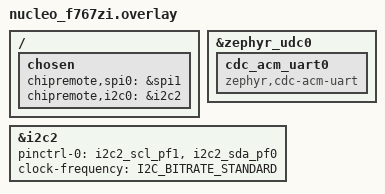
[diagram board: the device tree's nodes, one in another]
/ {
        chosen {
                chipremote,spi0 = &spi1;
                chipremote,i2c0 = &i2c1;
                chipremote,i2c0 = &i2c2;
        };
};

&zephyr_udc0 {
        cdc_acm_uart0: cdc_acm_uart0 {
                compatible = "zephyr,cdc-acm-uart";
        };
};

&i2c2 {
        pinctrl-0 = < &i2c2_scl_pf1 &i2c2_sda_pf0 >;
        pinctrl-names = "default";
        status = "okay";
	clock-frequency = <I2C_BITRATE_STANDARD>;
};
